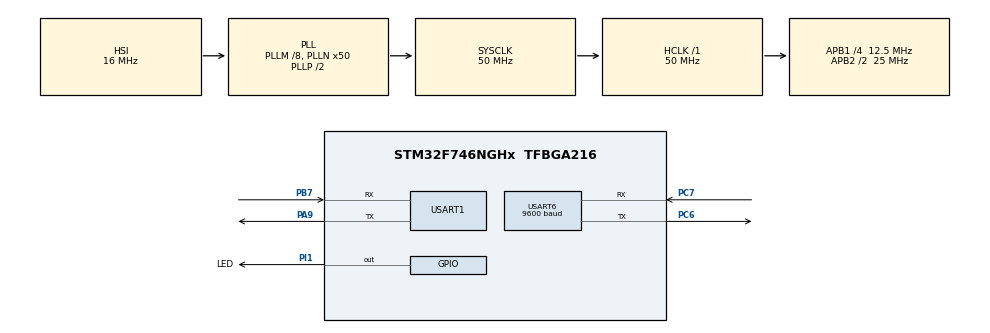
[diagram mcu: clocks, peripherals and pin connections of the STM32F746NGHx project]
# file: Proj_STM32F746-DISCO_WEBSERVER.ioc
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Mcu.Family=STM32F7
Mcu.Name=STM32F746NGHx
Mcu.Package=TFBGA216
NVIC.PriorityGroup=NVIC_PRIORITYGROUP_4
NVIC.USART1_IRQn=true\:0\:0\:false\:false\:true\:true\:true\:true
NVIC.USART6_IRQn=true\:0\:0\:false\:false\:true\:true\:true\:true
PA13.Mode=Serial_Wire
PA13.Signal=SYS_JTMS-SWDIO
PA14.Mode=Serial_Wire
PA14.Signal=SYS_JTCK-SWCLK
PA9.Mode=Asynchronous
PA9.Signal=USART1_TX
PB7.Mode=Asynchronous
PB7.Signal=USART1_RX
PC6.Mode=Asynchronous
PC6.Signal=USART6_TX
PC7.Mode=Asynchronous
PC7.Signal=USART6_RX
PH0/OSC_IN.Mode=HSE-External-Oscillator
PH0/OSC_IN.Signal=RCC_OSC_IN
PH1/OSC_OUT.Mode=HSE-External-Oscillator
PH1/OSC_OUT.Signal=RCC_OSC_OUT
PI1.GPIO_Label=LED
PI1.Signal=GPIO_Output
ProjectManager.HeapSize=0x200
ProjectManager.StackSize=0x400
ProjectManager.TargetToolchain=STM32CubeIDE
RCC.AHBFreq_Value=50000000
RCC.APB1CLKDivider=RCC_HCLK_DIV4
RCC.APB1Freq_Value=12500000
RCC.APB1TimFreq_Value=25000000
RCC.APB2CLKDivider=RCC_HCLK_DIV2
RCC.APB2Freq_Value=25000000
RCC.APB2TimFreq_Value=50000000
RCC.CortexFreq_Value=50000000
RCC.HCLKFreq_Value=50000000
RCC.HSE_VALUE=25000000
RCC.HSI_VALUE=16000000
RCC.PLL48CLockSelection=RCC_CLK48SOURCE_PLLSAIP
RCC.PLLI2SN=100
RCC.PLLM=8
RCC.PLLN=50
RCC.PLLQ=9
RCC.PLLSAIN=384
RCC.PLLSAIP=RCC_PLLSAIP_DIV8
RCC.PLLSAIR=5
RCC.PLLSAIRDiv=RCC_PLLSAIDIVR_8
RCC.SDMMCClockSelection=RCC_SDMMC1CLKSOURCE_CLK48
RCC.SYSCLKFreq_VALUE=50000000
RCC.SYSCLKSource=RCC_SYSCLKSOURCE_PLLCLK
RCC.USBFreq_Value=96000000
RCC.VCOOutputFreq_Value=100000000
USART1.VirtualMode-Asynchronous=VM_ASYNC
USART6.BaudRate=9600
USART6.OverSampling=UART_OVERSAMPLING_16
USART6.VirtualMode-Asynchronous=VM_ASYNC
board=STM32F746G-DISCO

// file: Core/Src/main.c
/* USER CODE BEGIN Header */
/**
  ******************************************************************************
  * @file           : main.c
  * @brief          : Main program body
  ******************************************************************************
  * @attention
  *
  * Copyright (c) 2022 STMicroelectronics.
  * All rights reserved.
  *
  * This software is licensed under terms that can be found in the LICENSE file
  * in the root directory of this software component.
  * If no LICENSE file comes with this software, it is provided AS-IS.
  *
  ******************************************************************************
  */
/* USER CODE END Header */
#include "main.h"

/* USER CODE BEGIN Includes */
#include "ESP8266_HAL.h"
/* USER CODE END Includes */

UART_HandleTypeDef huart1;
UART_HandleTypeDef huart6;

void SystemClock_Config(void);
static void MX_GPIO_Init(void);
static void MX_USART1_UART_Init(void);
static void MX_USART6_UART_Init(void);

int main(void)
{

  /* MCU Configuration--------------------------------------------------------*/

  /* Reset of all peripherals, Initializes the Flash interface and the Systick. */
  HAL_Init();

  /* Configure the system clock */
  SystemClock_Config();

  /* Initialize all configured peripherals */
  MX_GPIO_Init();
  MX_USART1_UART_Init();
  MX_USART6_UART_Init();
  /* USER CODE BEGIN 2 */
  ESP_Init("delameta", "bilano1407");
  /* USER CODE END 2 */

  /* Infinite loop */
  while (1)
  {

    /* USER CODE BEGIN 3 */
	  Server_Start();
  }
  /* USER CODE END 3 */
}

void SystemClock_Config(void)
{
  RCC_OscInitTypeDef RCC_OscInitStruct = {0};
  RCC_ClkInitTypeDef RCC_ClkInitStruct = {0};

  /** Configure the main internal regulator output voltage
  */
  __HAL_RCC_PWR_CLK_ENABLE();
  __HAL_PWR_VOLTAGESCALING_CONFIG(PWR_REGULATOR_VOLTAGE_SCALE3);

  /** Initializes the RCC Oscillators according to the specified parameters
  * in the RCC_OscInitTypeDef structure.
  */
  RCC_OscInitStruct.OscillatorType = RCC_OSCILLATORTYPE_HSI;
  RCC_OscInitStruct.HSIState = RCC_HSI_ON;
  RCC_OscInitStruct.HSICalibrationValue = RCC_HSICALIBRATION_DEFAULT;
  RCC_OscInitStruct.PLL.PLLState = RCC_PLL_ON;
  RCC_OscInitStruct.PLL.PLLSource = RCC_PLLSOURCE_HSI;
  RCC_OscInitStruct.PLL.PLLM = 8;
  RCC_OscInitStruct.PLL.PLLN = 50;
  RCC_OscInitStruct.PLL.PLLP = RCC_PLLP_DIV2;
  RCC_OscInitStruct.PLL.PLLQ = 9;
  if (HAL_RCC_OscConfig(&RCC_OscInitStruct) != HAL_OK)
  {
    Error_Handler();
  }

  /** Initializes the CPU, AHB and APB buses clocks
  */
  RCC_ClkInitStruct.ClockType = RCC_CLOCKTYPE_HCLK|RCC_CLOCKTYPE_SYSCLK
                              |RCC_CLOCKTYPE_PCLK1|RCC_CLOCKTYPE_PCLK2;
  RCC_ClkInitStruct.SYSCLKSource = RCC_SYSCLKSOURCE_PLLCLK;
  RCC_ClkInitStruct.AHBCLKDivider = RCC_SYSCLK_DIV1;
  RCC_ClkInitStruct.APB1CLKDivider = RCC_HCLK_DIV4;
  RCC_ClkInitStruct.APB2CLKDivider = RCC_HCLK_DIV2;

  if (HAL_RCC_ClockConfig(&RCC_ClkInitStruct, FLASH_LATENCY_1) != HAL_OK)
  {
    Error_Handler();
  }
}

static void MX_USART1_UART_Init(void)
{

  huart1.Instance = USART1;
  huart1.Init.BaudRate = 115200;
  huart1.Init.WordLength = UART_WORDLENGTH_8B;
  huart1.Init.StopBits = UART_STOPBITS_1;
  huart1.Init.Parity = UART_PARITY_NONE;
  huart1.Init.Mode = UART_MODE_TX_RX;
  huart1.Init.HwFlowCtl = UART_HWCONTROL_NONE;
  huart1.Init.OverSampling = UART_OVERSAMPLING_16;
  huart1.Init.OneBitSampling = UART_ONE_BIT_SAMPLE_DISABLE;
  huart1.AdvancedInit.AdvFeatureInit = UART_ADVFEATURE_NO_INIT;
  if (HAL_UART_Init(&huart1) != HAL_OK)
  {
    Error_Handler();
  }

}

static void MX_USART6_UART_Init(void)
{

  huart6.Instance = USART6;
  huart6.Init.BaudRate = 9600;
  huart6.Init.WordLength = UART_WORDLENGTH_8B;
  huart6.Init.StopBits = UART_STOPBITS_1;
  huart6.Init.Parity = UART_PARITY_NONE;
  huart6.Init.Mode = UART_MODE_TX_RX;
  huart6.Init.HwFlowCtl = UART_HWCONTROL_NONE;
  huart6.Init.OverSampling = UART_OVERSAMPLING_16;
  huart6.Init.OneBitSampling = UART_ONE_BIT_SAMPLE_DISABLE;
  huart6.AdvancedInit.AdvFeatureInit = UART_ADVFEATURE_NO_INIT;
  if (HAL_UART_Init(&huart6) != HAL_OK)
  {
    Error_Handler();
  }

}

static void MX_GPIO_Init(void)
{
  GPIO_InitTypeDef GPIO_InitStruct = {0};

  /* GPIO Ports Clock Enable */
  __HAL_RCC_GPIOA_CLK_ENABLE();
  __HAL_RCC_GPIOB_CLK_ENABLE();
  __HAL_RCC_GPIOI_CLK_ENABLE();
  __HAL_RCC_GPIOH_CLK_ENABLE();
  __HAL_RCC_GPIOC_CLK_ENABLE();

  /*Configure GPIO pin Output Level */
  HAL_GPIO_WritePin(LED_GPIO_Port, LED_Pin, GPIO_PIN_RESET);

  /*Configure GPIO pin : LED_Pin */
  GPIO_InitStruct.Pin = LED_Pin;
  GPIO_InitStruct.Mode = GPIO_MODE_OUTPUT_PP;
  GPIO_InitStruct.Pull = GPIO_NOPULL;
  GPIO_InitStruct.Speed = GPIO_SPEED_FREQ_LOW;
  HAL_GPIO_Init(LED_GPIO_Port, &GPIO_InitStruct);

}

void Error_Handler(void)
{
  __disable_irq();
  while (1)
  {
  }
}
